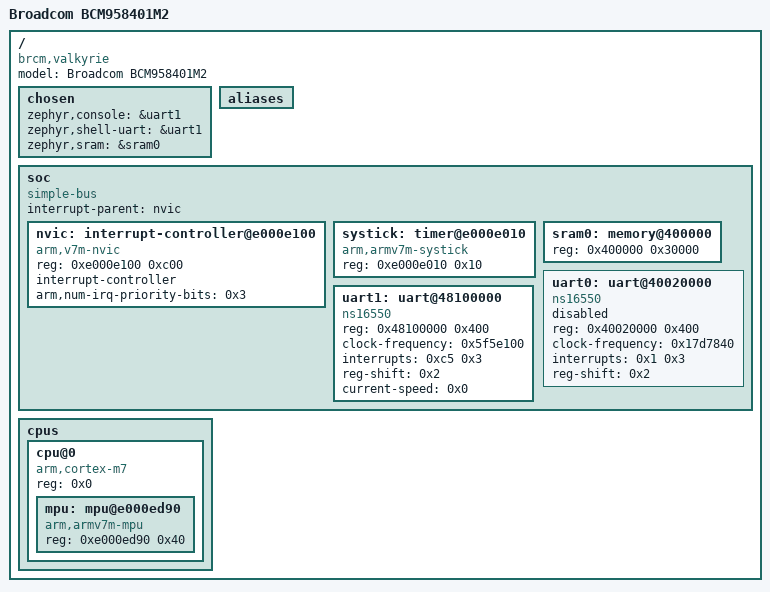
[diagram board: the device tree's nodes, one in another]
/dts-v1/;

/* node '/' defined in zephyr/dts/common/skeleton.dtsi:9 */
/ {
	model = "Broadcom BCM958401M2"; /* in zephyr/boards/brcm/bcm958401m2/bcm958401m2.dts:11 */
	compatible = "brcm,valkyrie";   /* in zephyr/boards/brcm/bcm958401m2/bcm958401m2.dts:12 */
	#address-cells = < 0x1 >;       /* in zephyr/boards/brcm/bcm958401m2/bcm958401m2.dts:13 */
	#size-cells = < 0x1 >;          /* in zephyr/boards/brcm/bcm958401m2/bcm958401m2.dts:14 */

	/* node '/chosen' defined in zephyr/dts/common/skeleton.dtsi:13 */
	chosen {
		zephyr,console = &uart1;    /* in zephyr/boards/brcm/bcm958401m2/bcm958401m2.dts:17 */
		zephyr,shell-uart = &uart1; /* in zephyr/boards/brcm/bcm958401m2/bcm958401m2.dts:18 */
		zephyr,sram = &sram0;       /* in zephyr/boards/brcm/bcm958401m2/bcm958401m2.dts:19 */
	};

	/* node '/aliases' defined in zephyr/dts/common/skeleton.dtsi:15 */
	aliases {
	};

	/* node '/soc' defined in zephyr/dts/arm/armv7-m.dtsi:6 */
	soc {
		#address-cells = < 0x1 >;     /* in zephyr/dts/arm/armv7-m.dtsi:7 */
		#size-cells = < 0x1 >;        /* in zephyr/dts/arm/armv7-m.dtsi:8 */
		compatible = "simple-bus";    /* in zephyr/dts/arm/armv7-m.dtsi:9 */
		interrupt-parent = < &nvic >; /* in zephyr/dts/arm/armv7-m.dtsi:10 */
		ranges;                       /* in zephyr/dts/arm/armv7-m.dtsi:11 */

		/* node '/soc/interrupt-controller@e000e100' defined in zephyr/dts/arm/armv7-m.dtsi:13 */
		nvic: interrupt-controller@e000e100 {
			#address-cells = < 0x1 >;            /* in zephyr/dts/arm/armv7-m.dtsi:14 */
			compatible = "arm,v7m-nvic";         /* in zephyr/dts/arm/armv7-m.dtsi:15 */
			reg = < 0xe000e100 0xc00 >;          /* in zephyr/dts/arm/armv7-m.dtsi:16 */
			interrupt-controller;                /* in zephyr/dts/arm/armv7-m.dtsi:17 */
			#interrupt-cells = < 0x2 >;          /* in zephyr/dts/arm/armv7-m.dtsi:18 */
			arm,num-irq-priority-bits = < 0x3 >; /* in zephyr/dts/arm/broadcom/valkyrie.dtsi:55 */
			phandle = < 0x1 >;                   /* in zephyr/dts/arm/armv7-m.dtsi:10 */
		};

		/* node '/soc/timer@e000e010' defined in zephyr/dts/arm/armv7-m.dtsi:21 */
		systick: timer@e000e010 {
			compatible = "arm,armv7m-systick"; /* in zephyr/dts/arm/armv7-m.dtsi:22 */
			reg = < 0xe000e010 0x10 >;         /* in zephyr/dts/arm/armv7-m.dtsi:23 */
		};

		/* node '/soc/memory@400000' defined in zephyr/dts/arm/broadcom/valkyrie.dtsi:29 */
		sram0: memory@400000 {
			device_type = "memory";     /* in zephyr/dts/arm/broadcom/valkyrie.dtsi:30 */
			reg = < 0x400000 0x30000 >; /* in zephyr/dts/arm/broadcom/valkyrie.dtsi:31 */
		};

		/* node '/soc/uart@40020000' defined in zephyr/dts/arm/broadcom/valkyrie.dtsi:34 */
		uart0: uart@40020000 {
			compatible = "ns16550";          /* in zephyr/dts/arm/broadcom/valkyrie.dtsi:35 */
			reg = < 0x40020000 0x400 >;      /* in zephyr/dts/arm/broadcom/valkyrie.dtsi:36 */
			clock-frequency = < 0x17d7840 >; /* in zephyr/dts/arm/broadcom/valkyrie.dtsi:37 */
			interrupts = < 0x1 0x3 >;        /* in zephyr/dts/arm/broadcom/valkyrie.dtsi:38 */
			reg-shift = < 0x2 >;             /* in zephyr/dts/arm/broadcom/valkyrie.dtsi:39 */
			status = "disabled";             /* in zephyr/dts/arm/broadcom/valkyrie.dtsi:40 */
		};

		/* node '/soc/uart@48100000' defined in zephyr/dts/arm/broadcom/valkyrie.dtsi:43 */
		uart1: uart@48100000 {
			compatible = "ns16550";          /* in zephyr/dts/arm/broadcom/valkyrie.dtsi:44 */
			reg = < 0x48100000 0x400 >;      /* in zephyr/dts/arm/broadcom/valkyrie.dtsi:45 */
			clock-frequency = < 0x5f5e100 >; /* in zephyr/dts/arm/broadcom/valkyrie.dtsi:46 */
			interrupts = < 0xc5 0x3 >;       /* in zephyr/dts/arm/broadcom/valkyrie.dtsi:47 */
			reg-shift = < 0x2 >;             /* in zephyr/dts/arm/broadcom/valkyrie.dtsi:48 */
			current-speed = < 0x0 >;         /* in zephyr/boards/brcm/bcm958401m2/bcm958401m2.dts:28 */
			status = "okay";                 /* in zephyr/boards/brcm/bcm958401m2/bcm958401m2.dts:29 */
		};
	};

	/* node '/cpus' defined in zephyr/dts/arm/broadcom/valkyrie.dtsi:10 */
	cpus {
		#address-cells = < 0x1 >; /* in zephyr/dts/arm/broadcom/valkyrie.dtsi:11 */
		#size-cells = < 0x0 >;    /* in zephyr/dts/arm/broadcom/valkyrie.dtsi:12 */

		/* node '/cpus/cpu@0' defined in zephyr/dts/arm/broadcom/valkyrie.dtsi:14 */
		cpu@0 {
			device_type = "cpu";          /* in zephyr/dts/arm/broadcom/valkyrie.dtsi:15 */
			compatible = "arm,cortex-m7"; /* in zephyr/dts/arm/broadcom/valkyrie.dtsi:16 */
			reg = < 0x0 >;                /* in zephyr/dts/arm/broadcom/valkyrie.dtsi:17 */
			#address-cells = < 0x1 >;     /* in zephyr/dts/arm/broadcom/valkyrie.dtsi:18 */
			#size-cells = < 0x1 >;        /* in zephyr/dts/arm/broadcom/valkyrie.dtsi:19 */

			/* node '/cpus/cpu@0/mpu@e000ed90' defined in zephyr/dts/arm/broadcom/valkyrie.dtsi:21 */
			mpu: mpu@e000ed90 {
				compatible = "arm,armv7m-mpu"; /* in zephyr/dts/arm/broadcom/valkyrie.dtsi:22 */
				reg = < 0xe000ed90 0x40 >;     /* in zephyr/dts/arm/broadcom/valkyrie.dtsi:23 */
			};
		};
	};
};
